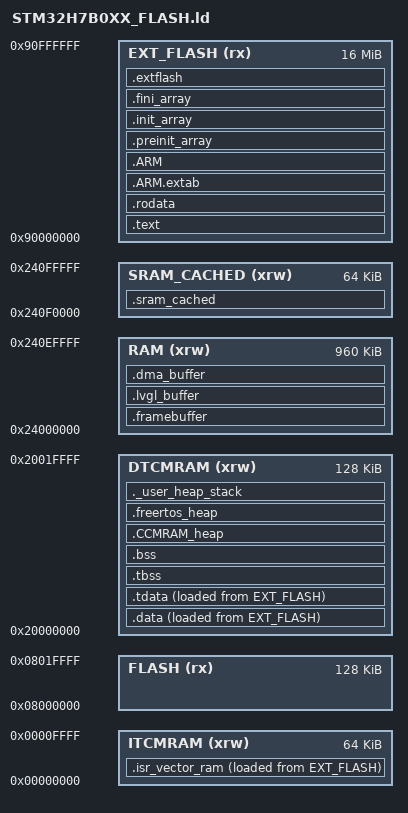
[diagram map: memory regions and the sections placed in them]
/*
******************************************************************************
**

**  File        : LinkerScript.ld
**
**  Author		: STM32CubeMX
**
**  Abstract    : Linker script for STM32H7B0VBTx series
**                128Kbytes FLASH and 1216Kbytes RAM
**
**                Set heap size, stack size and stack location according
**                to application requirements.
**
**                Set memory bank area and size if external memory is used.
**
**  Target      : STMicroelectronics STM32
**
**  Distribution: The file is distributed “as is,” without any warranty
**                of any kind.
**
*****************************************************************************
** @attention
**
** <h2><center>&copy; COPYRIGHT(c) 2025 STMicroelectronics</center></h2>
**
** Redistribution and use in source and binary forms, with or without modification,
** are permitted provided that the following conditions are met:
**   1. Redistributions of source code must retain the above copyright notice,
**      this list of conditions and the following disclaimer.
**   2. Redistributions in binary form must reproduce the above copyright notice,
**      this list of conditions and the following disclaimer in the documentation
**      and/or other materials provided with the distribution.
**   3. Neither the name of STMicroelectronics nor the names of its contributors
**      may be used to endorse or promote products derived from this software
**      without specific prior written permission.
**
** THIS SOFTWARE IS PROVIDED BY THE COPYRIGHT HOLDERS AND CONTRIBUTORS "AS IS"
** AND ANY EXPRESS OR IMPLIED WARRANTIES, INCLUDING, BUT NOT LIMITED TO, THE
** IMPLIED WARRANTIES OF MERCHANTABILITY AND FITNESS FOR A PARTICULAR PURPOSE ARE
** DISCLAIMED. IN NO EVENT SHALL THE COPYRIGHT HOLDER OR CONTRIBUTORS BE LIABLE
** FOR ANY DIRECT, INDIRECT, INCIDENTAL, SPECIAL, EXEMPLARY, OR CONSEQUENTIAL
** DAMAGES (INCLUDING, BUT NOT LIMITED TO, PROCUREMENT OF SUBSTITUTE GOODS OR
** SERVICES; LOSS OF USE, DATA, OR PROFITS; OR BUSINESS INTERRUPTION) HOWEVER
** CAUSED AND ON ANY THEORY OF LIABILITY, WHETHER IN CONTRACT, STRICT LIABILITY,
** OR TORT (INCLUDING NEGLIGENCE OR OTHERWISE) ARISING IN ANY WAY OUT OF THE USE
** OF THIS SOFTWARE, EVEN IF ADVISED OF THE POSSIBILITY OF SUCH DAMAGE.
**
*****************************************************************************
*/

/* Entry Point */
ENTRY(Reset_Handler)

/* Specify the memory areas */
MEMORY
{
DTCMRAM (xrw)      : ORIGIN = 0x20000000, LENGTH = 128K
RAM (xrw)          : ORIGIN = 0x24000000, LENGTH = 960K
SRAM_CACHED (xrw)  : ORIGIN = 0x240F0000, LENGTH = 64K
ITCMRAM (xrw)      : ORIGIN = 0x00000000, LENGTH = 64K
FLASH (rx)         : ORIGIN = 0x8000000,  LENGTH = 128K
EXT_FLASH (rx)     : ORIGIN = 0x90000000, LENGTH = 16M
}

/* Highest address of the user mode stack */
_estack = ORIGIN(DTCMRAM) + LENGTH(DTCMRAM);    /* end of RAM */
_sstack = _estack - _Min_Stack_Size;
/* Generate a link error if heap and stack don't fit into RAM */
_Min_Heap_Size = 0x1000;      /* required amount of heap  */
_Min_Stack_Size = 0x1000; /* required amount of stack */

/* Define output sections */
SECTIONS
{


  /* Vector table copy in ITCMRAM for fast interrupt response */
  .isr_vector_ram : ALIGN(4)
  {
    . = ALIGN(4);
    _isr_vector_ram_start = .;
    KEEP(*(.isr_vector_ram))
    . = ALIGN(4);
    _isr_vector_ram_end = .;
  } >ITCMRAM AT> EXT_FLASH

  /* The program code goes to external FLASH */
  .text :
  {
    . = ALIGN(4);
    _stext = .;
    *(.text)           /* .text sections (code) */
    *(.text*)          /* .text* sections (code) */
    *(.glue_7)         /* glue arm to thumb code */
    *(.glue_7t)        /* glue thumb to arm code */
    *(.eh_frame)

    KEEP (*(.init))
    KEEP (*(.fini))

    . = ALIGN(4);
    _etext = .;        /* define a global symbols at end of code */
  } >EXT_FLASH

  /* Constant data goes into EXT_FLASH */
  .rodata :
  {
    . = ALIGN(4);
    *(.rodata)         /* .rodata sections (constants, strings, etc.) */
    *(.rodata*)        /* .rodata* sections (constants, strings, etc.) */
    . = ALIGN(4);
  } >EXT_FLASH

  .ARM.extab (READONLY) : /* The "READONLY" keyword is only supported in GCC11 and later, remove it if using GCC10 or earlier. */
  {
    . = ALIGN(4);
    *(.ARM.extab* .gnu.linkonce.armextab.*)
    . = ALIGN(4);
  } >EXT_FLASH

  .ARM (READONLY) : /* The "READONLY" keyword is only supported in GCC11 and later, remove it if using GCC10 or earlier. */
  {
    . = ALIGN(4);
    __exidx_start = .;
    *(.ARM.exidx*)
    __exidx_end = .;
    . = ALIGN(4);
  } >EXT_FLASH

  .preinit_array (READONLY) : /* The "READONLY" keyword is only supported in GCC11 and later, remove it if using GCC10 or earlier. */
  {
    . = ALIGN(4);
    PROVIDE_HIDDEN (__preinit_array_start = .);
    KEEP (*(.preinit_array*))
    PROVIDE_HIDDEN (__preinit_array_end = .);
    . = ALIGN(4);
  } >EXT_FLASH

  .init_array (READONLY) : /* The "READONLY" keyword is only supported in GCC11 and later, remove it if using GCC10 or earlier. */
  {
    . = ALIGN(4);
    PROVIDE_HIDDEN (__init_array_start = .);
    KEEP (*(SORT(.init_array.*)))
    KEEP (*(.init_array*))
    PROVIDE_HIDDEN (__init_array_end = .);
    . = ALIGN(4);
  } >EXT_FLASH

  .fini_array (READONLY) : /* The "READONLY" keyword is only supported in GCC11 and later, remove it if using GCC10 or earlier. */
  {
    . = ALIGN(4);
    PROVIDE_HIDDEN (__fini_array_start = .);
    KEEP (*(SORT(.fini_array.*)))
    KEEP (*(.fini_array*))
    PROVIDE_HIDDEN (__fini_array_end = .);
    . = ALIGN(4);
  } >EXT_FLASH

  /* used by the startup to initialize data */
  _sidata = LOADADDR(.data);

  /* Initialized data sections goes into RAM, load LMA copy after code */
  .data :
  {
    . = ALIGN(4);
    _sdata = .;        /* create a global symbol at data start */
    *(.data)           /* .data sections */
    *(.data*)          /* .data* sections */
    *(.RamFunc)        /* .RamFunc sections */
    *(.RamFunc*)       /* .RamFunc* sections */

    . = ALIGN(4);
  } >DTCMRAM AT> EXT_FLASH

 /* Initialized TLS data section */
  .tdata : ALIGN(4)
  {
    *(.tdata .tdata.* .gnu.linkonce.td.*)
    . = ALIGN(4);
    _edata = .;        /* define a global symbol at data end */
    PROVIDE(__data_end = .);
    PROVIDE(__tdata_end = .);
  } >DTCMRAM AT> EXT_FLASH

  PROVIDE( __tdata_start = ADDR(.tdata) );
  PROVIDE( __tdata_size = __tdata_end - __tdata_start );

  PROVIDE( __data_start = ADDR(.data) );
  PROVIDE( __data_size = __data_end - __data_start );

  PROVIDE( __tdata_source = LOADADDR(.tdata) );
  PROVIDE( __tdata_source_end = LOADADDR(.tdata) + SIZEOF(.tdata) );
  PROVIDE( __tdata_source_size = __tdata_source_end - __tdata_source );

  PROVIDE( __data_source = LOADADDR(.data) );
  PROVIDE( __data_source_end = __tdata_source_end );
  PROVIDE( __data_source_size = __data_source_end - __data_source );
  /* Uninitialized data section */
  .tbss (NOLOAD) : ALIGN(4)
  {
     /* This is used by the startup in order to initialize the .bss secion */
    _sbss = .;         /* define a global symbol at bss start */
    __bss_start__ = _sbss;
    *(.tbss .tbss.*)
    . = ALIGN(4);
    PROVIDE( __tbss_end = . );
  } >DTCMRAM

  PROVIDE( __tbss_start = ADDR(.tbss) );
  PROVIDE( __tbss_size = __tbss_end - __tbss_start );
  PROVIDE( __tbss_offset = ADDR(.tbss) - ADDR(.tdata) );

  PROVIDE( __tls_base = __tdata_start );
  PROVIDE( __tls_end = __tbss_end );
  PROVIDE( __tls_size = __tls_end - __tls_base );
  PROVIDE( __tls_align = MAX(ALIGNOF(.tdata), ALIGNOF(.tbss)) );
  PROVIDE( __tls_size_align = (__tls_size + __tls_align - 1) & ~(__tls_align - 1) );
  PROVIDE( __arm32_tls_tcb_offset = MAX(8, __tls_align) );
  PROVIDE( __arm64_tls_tcb_offset = MAX(16, __tls_align) );

  .bss (NOLOAD) : ALIGN(4)
  {
    *(.bss)
    *(.bss*)
    *(COMMON)

      . = ALIGN(4);
    _ebss = .;         /* define a global symbol at bss end */
    __bss_end__ = _ebss;
      PROVIDE( __bss_end = .);
  } >DTCMRAM
  PROVIDE( __non_tls_bss_start = ADDR(.bss) );

  PROVIDE( __bss_start = __tbss_start );
  PROVIDE( __bss_size = __bss_end - __bss_start );

  /*==========================================================================
   * LVGL heap - cached DTCMRAM for low latency
   *==========================================================================*/
  .CCMRAM_heap (NOLOAD) : ALIGN(32)
  {
    . = ALIGN(32);
    _CCMRAM_heap_start = .;
    *(.CCMRAM_heap)
    . = ALIGN(32);
    _CCMRAM_heap_end = .;
  } >DTCMRAM

  /*==========================================================================
   * FreeRTOS heap - cached DTCMRAM for low latency (15KB)
   *==========================================================================*/
  .freertos_heap (NOLOAD) : ALIGN(32)
  {
    . = ALIGN(32);
    _freertos_heap_start = .;
    *(.freertos_heap)
    *(.HeapSection*)
    . = ALIGN(32);
    _freertos_heap_end = .;
  } >DTCMRAM

  /*==========================================================================
   * Non-cached DMA buffers (AXI SRAM - CPU and DMA can access without cache)
   *==========================================================================*/
  /* LTDC Full Framebuffer - 480 x 800 x 2 bytes (RGB565) = 768,000 bytes (~750KB)
     This is the display buffer that LTDC reads from */
  .framebuffer (NOLOAD) : ALIGN(32)
  {
    . = ALIGN(32);
    _framebuffer_start = .;
    *(.framebuffer)
    . = ALIGN(32);
    _framebuffer_end = .;
  } >RAM

  /* LVGL Drawing Buffer - partial buffer for LVGL rendering (~1/5 screen height)
     480 x 160 x 2 bytes = 153,600 bytes */
  .lvgl_buffer (NOLOAD) : ALIGN(32)
  {
    . = ALIGN(32);
    _lvgl_buffer_start = .;
    *(.lvgl_buffer)
    . = ALIGN(32);
    _lvgl_buffer_end = .;
  } >RAM

  /* ADC DMA buffer - 8 channels x 32 samples x 2 bytes = 512 bytes */
  .dma_buffer (NOLOAD) : ALIGN(32)
  {
    . = ALIGN(32);
    _dma_buffer_start = .;
    *(.dma_buffer)
    . = ALIGN(32);
    _dma_buffer_end = .;
  } >RAM
  /*==========================================================================
   * SRAM_CACHED region - last 64KB of AXI SRAM (cached)
   * Use this for data that needs cache (CPU reads frequently)
   *==========================================================================*/
  .sram_cached (NOLOAD) : ALIGN(32)
  {
    . = ALIGN(32);
    _sram_cached_start = .;
    *(.sram_cached)
    . = ALIGN(32);
    _sram_cached_end = .;
  } >SRAM_CACHED

  /*==========================================================================
   * End of non-cached regions
   *==========================================================================*/

  /*==========================================================================
   * External FLASH - OSPI1 memory mapped flash (16MB)
   * Large code and data go here
   *==========================================================================*/
  .extflash :
  {
    . = ALIGN(4);
    _extflash_start = .;
    *(.extflash*)
    . = ALIGN(4);
    _extflash_end = .;
  } >EXT_FLASH

  /* User_heap_stack section, used to check that there is enough RAM left */
  ._user_heap_stack (NOLOAD) :
  {
    . = ALIGN(8);
    PROVIDE ( end = . );
    PROVIDE ( _end = . );
    . = . + _Min_Heap_Size;
    . = . + _Min_Stack_Size;
    . = ALIGN(8);
  } >DTCMRAM



  /* Remove information from the standard libraries */
  /DISCARD/ :
  {
    libc.a:* ( * )
    libm.a:* ( * )
    libgcc.a:* ( * )
  }

}
